# STM32H757xx_CM4 register map
File version: 1.0
Registers are 32-bit, read-write, reset 0x0 unless marked. A register's access mark holds for its fields unless they carry their own. Offsets are from the block's base; [hi:lo] are bit positions; {n}, {i} and the like mark numbered series.

## COMP1
Base 0x5800380C
Same registers: COMP2 0x58003810
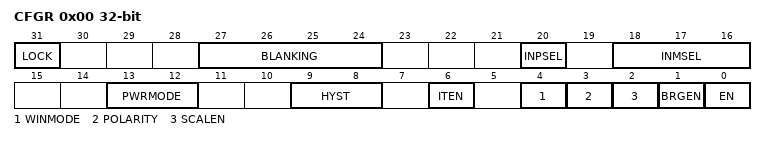
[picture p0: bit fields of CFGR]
0x00 CFGR — Comparator configuration register
  [31] LOCK — COMPx Lock Bit
  [27:24] BLANKING — COMPx blanking source selection bits
    0=NONE (Comparator output without blanking); 1=TIM1_OC5 (Comparator output blanking source TIM1 OC5 (common to all COMP instances: COMP1, COMP2)); 2=TIM2_OC3 (Comparator output blanking source TIM2 OC3 (common to all COMP instances: COMP1, COMP2)); 3=TIM3_OC3 (Comparator output blanking source TIM3 OC3 (common to all COMP instances: COMP1, COMP2)); 4=TIM3_OC4 (Comparator output blanking source TIM3 OC4 (common to all COMP instances: COMP1, COMP2)); 5=TIM8_OC5 (Comparator output blanking source TIM8 OC5 (common to all COMP instances: COMP1, COMP2)); 6=TIM15_OC1 (Comparator output blanking source TIM15 OC1 (common to all COMP instances: COMP1, COMP2))
  [20] INPSEL — COMPx input plus selection bit
  [18:16] INMSEL — COMPx input minus selection bit
  [13:12] PWRMODE — COMPx Power Mode of the comparator
    0=HIGHSPEED (COMP power mode to high speed); 1=MEDIUMSPEED (COMP power mode to medium speed); 3=ULTRALOWPOWER (COMP power mode to ultra-low power)
  [9:8] HYST — COMPx hysteresis selection bits
    0=NONE (No hysteresis); 1=LOW (Hysteresis level low); 2=MEDIUM (Hysteresis level medium); 3=HIGH (Hysteresis level high)
  [6] ITEN — COMPx interrupt enable
  [4] WINMODE — COMPx Windows mode selection bit
    0=DISABLE (Window mode disable: Comparators 1 and 2 are independent); 1=COMP1_INPUT_PLUS_COMMON (Window mode enable: Comparators instances pair COMP1 and COMP2 have their input plus connected together. The common input is COMP1 input plus (COMP2 input plus is no more accessible).)
  [3] POLARITY — COMPx polarity selection bit
    0=NONINVERTED (COMP output polarity is not inverted: comparator output is high when the plus (non-inverting) input is at a higher voltage than the minus (inverting) input); 1=INVERTED (COMP output polarity is inverted: comparator output is low when the plus (non-inverting) input is at a lower voltage than the minus (inverting) input)
  [2] SCALEN — COMPx Voltage scaler enable bit
  [1] BRGEN — COMPx Scaler bridge enable
  [0] EN — COMPx enable bit

## VREFBUF
Base 0x58003C00
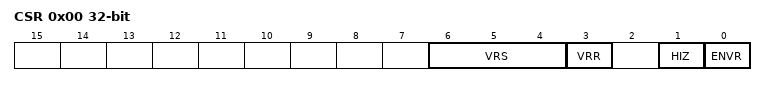
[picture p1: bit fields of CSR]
0x00 CSR — VREFBUF control and status register
  [6:4] VRS — Voltage reference scale
  [3] VRR — Voltage reference buffer ready
  [1] HIZ — High impedance mode
  [0] ENVR — Voltage reference buffer enable
0x04 CCR — VREFBUF calibration and control register
  [5:0] TRIM — TRIM[5:0] bits (Trimming code)

## IWDG1 — Independent WATCHDOG
Base 0x58004800
Same registers: IWDG2 0x58004C00
0x00 KR — IWDG Key register
  [15:0] KEY — Key value (write only, read 0000h)
0x04 PR — IWDG Prescaler register
  [2:0] PR — PR[2:0] (Prescaler divider)
0x08 RLR — IWDG Reload register
  [11:0] RL — Watchdog counter reload value
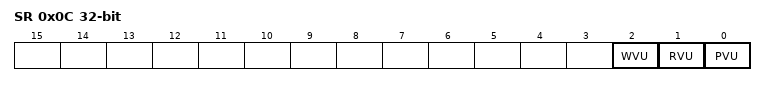
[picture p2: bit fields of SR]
0x0C SR — IWDG Status register
  [2] WVU — Watchdog counter window value update
  [1] RVU — Watchdog counter reload value update
  [0] PVU — Watchdog prescaler value update
0x10 WINR — IWDG Window register
  [11:0] WIN — Watchdog counter window value

## GPIOA — General Purpose I/O
Base 0x58020000
Same registers: GPIOB 0x58020400, GPIOC 0x58020800, GPIOD 0x58020C00, GPIOE 0x58021000, GPIOF 0x58021400, GPIOG 0x58021800, GPIOH 0x58021C00, GPIOI 0x58022000, GPIOJ 0x58022400, GPIOK 0x58022800
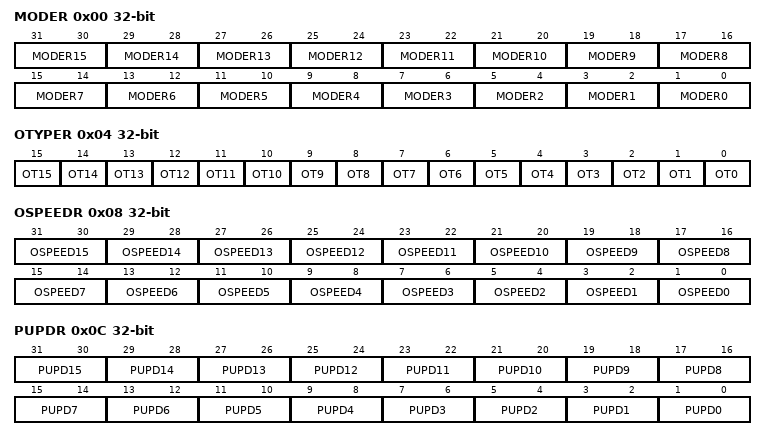
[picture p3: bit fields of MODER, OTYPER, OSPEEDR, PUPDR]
0x00 MODER — GPIO port mode register
  [2n+1:2n] MODER{n} (n=0..15)
0x04 OTYPER — GPIO port output type register
  [n] OT{n} (n=0..15)
0x08 OSPEEDR — GPIO port output speed register
  [2n+1:2n] OSPEED{n} (n=0..15)
0x0C PUPDR — GPIO port pull-up/pull-down register
  [2n+1:2n] PUPD{n} (n=0..15)
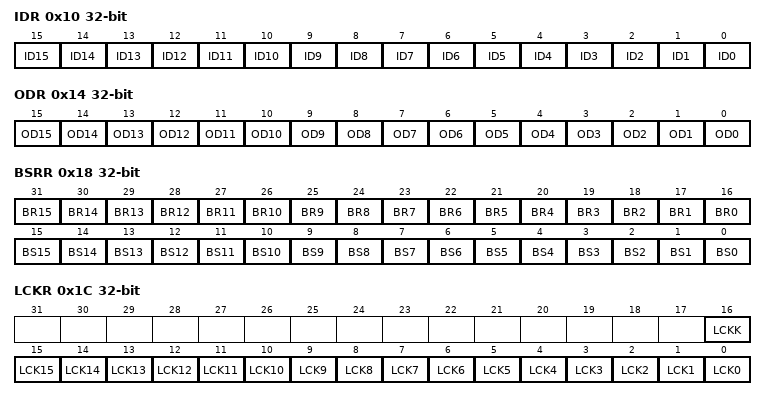
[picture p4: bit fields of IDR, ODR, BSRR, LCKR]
0x10 IDR — GPIO port input data register
  [n] ID{n} (n=0..15)
0x14 ODR — GPIO port output data register
  [n] OD{n} (n=0..15)
0x18 BSRR — GPIO port bit set/reset
  [n+16] BR{n} (n=0..15), [n] BS{n} (n=0..15)
0x1C LCKR — GPIO port configuration lock register
  [16] LCKK, [n] LCK{n} (n=0..15)
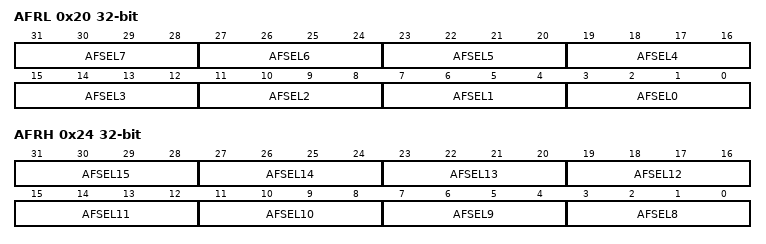
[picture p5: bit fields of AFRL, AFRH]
0x20 AFRL — GPIO alternate function registers
  [4n+3:4n] AFSEL{n} (n=0..7)
0x24 AFRH — GPIO alternate function registers
  [4n-29:4n-32] AFSEL{n} (n=8..15)
